# PIC32CM5164JH01064 register map
Vendor: Microchip Technology; Series: PIC32CMJH01; File version: 0
CPU: CM0+ r0p0, selectable endian, MPU, no FPU, VTOR, 2 interrupt priority bits
Registers are 32-bit, read-write, reset 0x0 unless marked. A register's access mark holds for its fields unless they carry their own. Offsets are from the block's base; [hi:lo] are bit positions; {n}, {i} and the like mark numbered series; 'fields as' and 'values as' point back to an identical list.

## DAC — Digital Analog Converter
Base 0x42005000; register names take the prefix DAC_
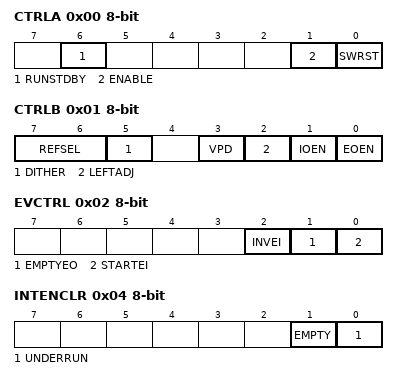
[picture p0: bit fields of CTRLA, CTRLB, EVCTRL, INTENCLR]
0x00 CTRLA 8-bit — Control A
  [6] RUNSTDBY — Run in Standby
  [1] ENABLE
  [0] SWRST — Software Reset
0x01 CTRLB 8-bit — Control B
  [7:6] REFSEL — Reference Selection
    0=INTREF (Internal Voltage Reference); 1=AVDD (Analog Voltage Supply); 2=VREFA (External Voltage Reference A (shared with ADC))
  [5] DITHER — Dither Enable
  [3] VPD — Voltage Pump Disable
  [2] LEFTADJ — Left Adjusted Data
  [1] IOEN — Internal Output Enable
  [0] EOEN — External Output Enable
0x02 EVCTRL 8-bit — Event Control
  [2] INVEI — Invert Event Input
  [1] EMPTYEO — Data Buffer Empty Event Output
  [0] STARTEI — Start Conversion Event Input
0x04 INTENCLR 8-bit — Interrupt Enable Clear
  [1] EMPTY — Data Buffer Empty Interrupt Enable
  [0] UNDERRUN — Underrun Interrupt Enable
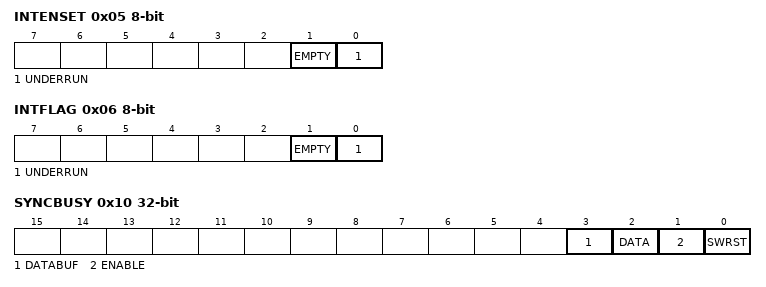
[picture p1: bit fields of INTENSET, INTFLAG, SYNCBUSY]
0x05 INTENSET 8-bit — Interrupt Enable Set
  fields as INTENCLR
0x06 INTFLAG 8-bit — Interrupt Flag Status and Clear
  [1] EMPTY — Data Buffer Empty
  [0] UNDERRUN
0x07 STATUS 8-bit ro
  [0] READY — DAC Ready
0x08 DATA 16-bit wo
  [15:0] DATA — Data value to be converted
0x0C DATABUF 16-bit wo — Data Buffer
0x10 SYNCBUSY ro — Synchronization Busy
  [3] DATABUF — Data Buffer
  [2] DATA
  [1] ENABLE — DAC Enable Status
  [0] SWRST — Software Reset
0x14 DBGCTRL 8-bit — Debug Control
  [0] DBGRUN — Debug Run

## DIVAS — Divide and Square Root Accelerator
Base 0x48000000; register names take the prefix DIVAS_
Same registers: DIVAS_IOBUS 0x60000200 (register names take the prefix DIVAS_IOBUS_)
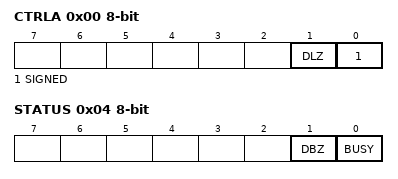
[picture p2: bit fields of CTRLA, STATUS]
0x00 CTRLA 8-bit — Control
  [1] DLZ — Disable Leading Zero Optimization
  [0] SIGNED
0x04 STATUS 8-bit
  [1] DBZ — Writing a one to this bit clears DBZ to zero
  [0] BUSY — DIVAS Accelerator Busy
0x08 DIVIDEND
0x0C DIVISOR
0x10 RESULT ro
0x14 REM ro — Remainder
0x18 SQRNUM — Square Root Input

## EIC — External Interrupt Controller
Base 0x40002800; register names take the prefix EIC_
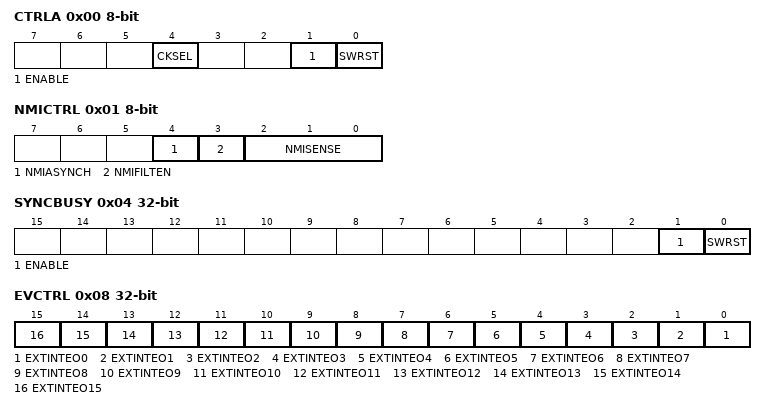
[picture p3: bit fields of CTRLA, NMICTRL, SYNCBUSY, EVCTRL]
0x00 CTRLA 8-bit — Control A
  [4] CKSEL — Clock Selection
    0=CLK_GCLK (Clocked by GCLK); 1=CLK_ULP32K (Clocked by ULP32K)
  [1] ENABLE
  [0] SWRST — Software Reset
0x01 NMICTRL 8-bit — Non-Maskable Interrupt Control
  [4] NMIASYNCH — Asynchronous Edge Detection Mode
    0=SYNC (Edge detection is clock synchronously operated); 1=ASYNC (Edge detection is clock asynchronously operated)
  [3] NMIFILTEN — Non-Maskable Interrupt Filter Enable
  [2:0] NMISENSE — Non-Maskable Interrupt Sense Configuration
    0=NONE (No detection); 1=RISE (Rising-edge detection); 2=FALL (Falling-edge detection); 3=BOTH (Both-edges detection); 4=HIGH (High-level detection); 5=LOW (Low-level detection)
0x02 NMIFLAG 8-bit — Non-Maskable Interrupt Flag Status and Clear
  [0] NMI — Non-Maskable Interrupt
0x04 SYNCBUSY ro — Synchronization Busy
  [1] ENABLE — Enable Synchronization Busy Status
  [0] SWRST — Software Reset Synchronization Busy Status
0x08 EVCTRL — Event Control
  [n] EXTINTEO{n} (n=0..15) — External Interrupt {n} Event Output Enable
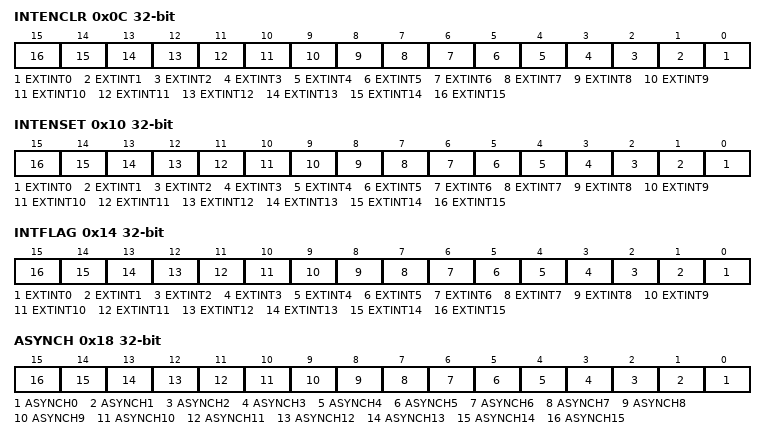
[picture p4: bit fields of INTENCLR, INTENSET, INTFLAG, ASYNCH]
0x0C INTENCLR — Interrupt Enable Clear
  [n] EXTINT{n} (n=0..15) — External Interrupt {n} Enable
0x10 INTENSET — Interrupt Enable Set
  [n] EXTINT{n} (n=0..15) — External Interrupt {n} Enable
0x14 INTFLAG — Interrupt Flag Status and Clear
  [n] EXTINT{n} (n=0..15) — External Interrupt {n}
0x18 ASYNCH — External Interrupt Asynchronous Mode
  [all] fields
    values as NMICTRL.NMIASYNCH
  [n] ASYNCH{n} (n=0..15) — Asynchronous Edge Detection Mode of EXTINT{n}
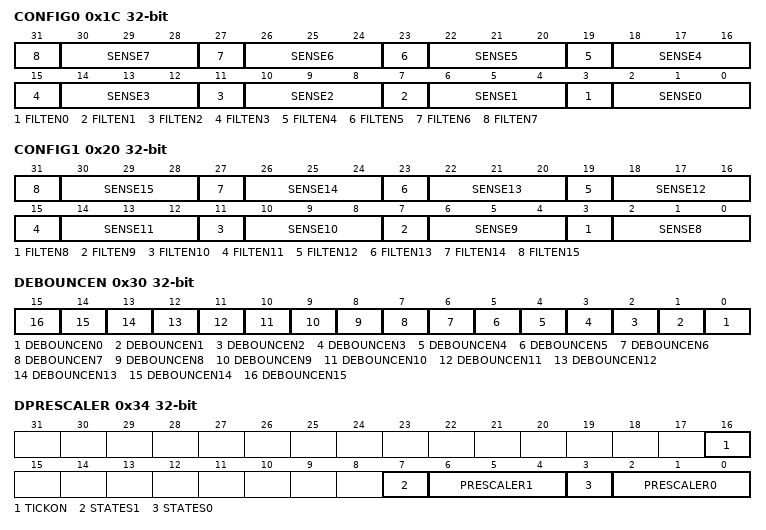
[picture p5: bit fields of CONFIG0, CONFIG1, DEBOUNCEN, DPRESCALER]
0x1C CONFIG0 — External Interrupt Sense Configuration
  [4n+3] FILTEN{n} (n=0..7) — Filter Enable {n}
  [4n+2:4n] SENSE{n} (n=0..7) — Input Sense Configuration {n}
    0=NONE (No detection); 1=RISE (Rising edge detection); 2=FALL (Falling edge detection); 3=BOTH (Both edges detection); 4=HIGH (High level detection); 5=LOW (Low level detection)
0x20 CONFIG1 — External Interrupt Sense Configuration
  [4n-29] FILTEN{n} (n=8..15) — Filter Enable {n}
  [4n-30:4n-32] SENSE{n} (n=8..15) — Input Sense Configuration {n}
    values as CONFIG0.SENSE0
0x30 DEBOUNCEN — Debouncer Enable
  [n] DEBOUNCEN{n} (n=0..15) — Debouncer Enable of EXTINT{n}
0x34 DPRESCALER — Debouncer Prescaler
  [16] TICKON — Pin Sampler frequency selection
    0=CLK_GCLK_EIC (Clocked by GCLK); 1=CLK_LFREQ (Clocked by Low Frequency Clock)
  [7] STATES1 — Debouncer number of states
    0=LFREQ3 (3 low frequency samples); 1=LFREQ7 (7 low frequency samples)
  [6:4] PRESCALER1 — Debouncer Prescaler
    0=DIV2 (EIC clock divided by 2); 1=DIV4 (EIC clock divided by 4); 2=DIV8 (EIC clock divided by 8); 3=DIV16 (EIC clock divided by 16); 4=DIV32 (EIC clock divided by 32); 5=DIV64 (EIC clock divided by 64); 6=DIV128 (EIC clock divided by 128); 7=DIV256 (EIC clock divided by 256)
  [3] STATES0 — Debouncer number of states
    values as STATES1
  [2:0] PRESCALER0 — Debouncer Prescaler
    values as PRESCALER1
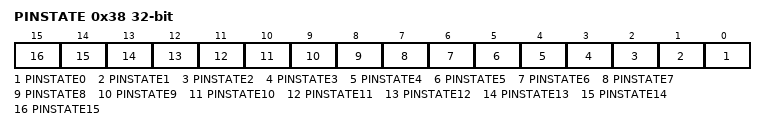
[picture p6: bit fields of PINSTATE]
0x38 PINSTATE ro
  [n] PINSTATE{n} (n=0..15) — Pin State of EXTINT{n}

## Notices in the file
Copyright (c) 2017 Microchip Technology Inc.
SPDX-License-Identifier: Apache-2.0
Licensed under the Apache License, Version 2.0 (the "License");
you may not use this file except in compliance with the License.
You may obtain a copy of the License at
http://www.apache.org/licenses/LICENSE-2.0
Unless required by applicable law or agreed to in writing, software
distributed under the License is distributed on an "AS IS" BASIS,
WITHOUT WARRANTIES OR CONDITIONS OF ANY KIND, either express or implied.
See the License for the specific language governing permissions and
limitations under the License.
